AUTOSAR XML (schema 4.0)
package /ExampleProject
  ecu configuration EcuConfig: ecu-name=ExampleECU, processor=ARM_CORTEX_M4, clock={core-clock=80000000, bus-clock=40000000}, memory={flash-size=512, ram-size=128}, module-configurations=[]
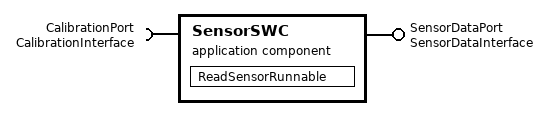
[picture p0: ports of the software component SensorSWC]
  application sw component type SensorSWC
    provide port SensorDataPort: provided-interface=SensorDataInterface
    require port CalibrationPort: required-interface=CalibrationInterface
    behavior SensorBehavior
      runnable ReadSensorRunnable: minimum-start-interval=0.01
        data send point SendSensorData: port-prototype=SensorDataPort
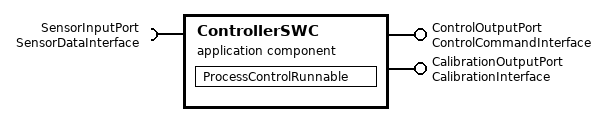
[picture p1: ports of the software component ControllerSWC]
  application sw component type ControllerSWC
    require port SensorInputPort: required-interface=SensorDataInterface
    provide port ControlOutputPort: provided-interface=ControlCommandInterface
    provide port CalibrationOutputPort: provided-interface=CalibrationInterface
    behavior ControllerBehavior
      runnable ProcessControlRunnable: minimum-start-interval=0.005
        data receive point by argument ReceiveSensorData: port-prototype=SensorInputPort
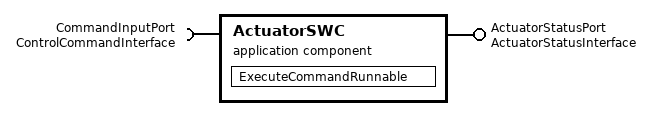
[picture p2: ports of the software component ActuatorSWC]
  application sw component type ActuatorSWC
    require port CommandInputPort: required-interface=ControlCommandInterface
    provide port ActuatorStatusPort: provided-interface=ActuatorStatusInterface
    behavior ActuatorBehavior
      runnable ExecuteCommandRunnable: minimum-start-interval=0.01
  4 x sender receiver interface:
    SensorDataInterface
      data SensorValue: type=Uint16Type, init-value=0
      data SensorStatus: type=Uint8Type, init-value=0
    ControlCommandInterface
      data CommandId: type=Uint8Type, init-value=0
      data CommandValue: type=Uint16Type, init-value=0
    CalibrationInterface
      data Gain: type=Uint16Type, init-value=1000
      data Offset: type=Sint16Type, init-value=0
    ActuatorStatusInterface
      data ActuatorPosition: type=Uint16Type, init-value=0
      data ErrorCode: type=Uint8Type, init-value=0
  impl type Uint8Type: category=VALUE, base-type=Uint8BaseType, data-length=8
  impl type Uint16Type: category=VALUE, base-type=Uint16BaseType, data-length=16
  impl type Sint16Type: category=VALUE, base-type=Sint16BaseType, data-length=16
  base type Uint8BaseType: base-type-definition={base-type-size=8, base-type-encoding=NONE, mem-alignment=8, byte-order=big-endian}
  base type Uint16BaseType: base-type-definition={base-type-size=16, base-type-encoding=NONE, mem-alignment=16, byte-order=big-endian}
  base type Sint16BaseType: base-type-definition={base-type-size=16, base-type-encoding=2C, mem-alignment=16, byte-order=big-endian}
  module config OsConfig: definition=Os
    OsTask: OsTaskName=SensorTask, OsTaskPriority=5
  module config ComConfig: definition=Com
    ComGeneral: ComVersionInfoApi=1
  module config NvMConfig: definition=NvM
    NvMCommon
